# nrf51 register map
Vendor: Nordic Semiconductor; Series: nrf51; File version: 522
CPU: CM0 r3p1, little endian, no MPU, no FPU, 2 interrupt priority bits
Registers are 32-bit, read-write, reset 0x0 unless marked. A register's access mark holds for its fields unless they carry their own. Offsets are from the block's base; [hi:lo] are bit positions; {n}, {i} and the like mark numbered series; 'fields as' and 'values as' point back to an identical list.

## QDEC — Rotary decoder.
Base 0x40012000
0x00 TASKS_START wo — Start the quadrature decoder.
0x04 TASKS_STOP wo — Stop the quadrature decoder.
0x08 TASKS_READCLRACC wo — Transfers the content from ACC registers to ACCREAD registers, and clears the ACC registers.
0x100 EVENTS_SAMPLERDY — A new sample is written to the sample register.
0x104 EVENTS_REPORTRDY — REPORTPER number of samples accumulated in ACC register, and ACC register different than zero.
0x108 EVENTS_ACCOF — ACC or ACCDBL register overflow.
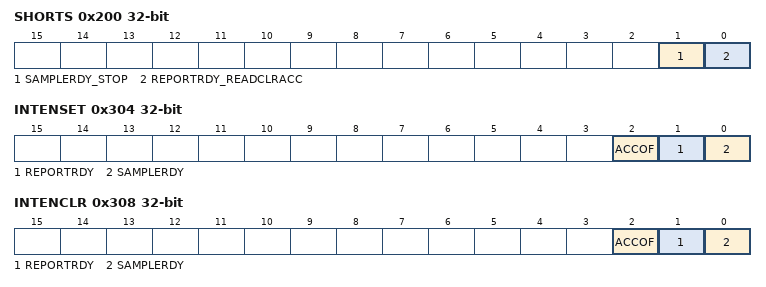
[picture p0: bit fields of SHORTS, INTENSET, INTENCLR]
0x200 SHORTS — Shortcuts for the QDEC.
  [1] SAMPLERDY_STOP — Shortcut between SAMPLERDY event and STOP task.
    0=Disabled (Shortcut disabled.); 1=Enabled (Shortcut enabled.)
  [0] REPORTRDY_READCLRACC — Shortcut between REPORTRDY event and READCLRACC task.
    values as SAMPLERDY_STOP
0x304 INTENSET — Interrupt enable set register.
  [all] fields
    on read: 0=Disabled (Interrupt disabled.); 1=Enabled (Interrupt enabled.) | on write: 1=Set (Enable interrupt on write.)
  [2] ACCOF — Enable interrupt on ACCOF event.
  [1] REPORTRDY — Enable interrupt on REPORTRDY event.
  [0] SAMPLERDY — Enable interrupt on SAMPLERDY event.
0x308 INTENCLR — Interrupt enable clear register.
  [all] fields
    on read: 0=Disabled (Interrupt disabled.); 1=Enabled (Interrupt enabled.) | on write: 1=Clear (Disable interrupt on write.)
  [2] ACCOF — Disable interrupt on ACCOF event.
  [1] REPORTRDY — Disable interrupt on REPORTRDY event.
  [0] SAMPLERDY — Disable interrupt on SAMPLERDY event.
0x500 ENABLE — Enable the QDEC.
  [0] ENABLE — Enable or disable QDEC.
    0=Disabled QDEC; 1=Enabled (Enable QDEC.)
0x504 LEDPOL — LED output pin polarity.
  [0] LEDPOL
    0=ActiveLow (LED output is active low.); 1=ActiveHigh (LED output is active high.)
0x508 SAMPLEPER — Sample period.
  [2:0] SAMPLEPER
    0=128us sample period; 1=256us sample period; 2=512us sample period; 3=1024us sample period; 4=2048us sample period; 5=4096us sample period; 6=8192us sample period; 7=16384us sample period
0x50C SAMPLE ro — Motion sample value.
  [31:0] SAMPLE — Last sample taken in compliment to 2.
0x510 REPORTPER — Number of samples to generate an EVENT_REPORTRDY.
  [2:0] REPORTPER
    0=10Smpl (10 samples per report.); 1=40Smpl (40 samples per report.); 2=80Smpl (80 samples per report.); 3=120Smpl (120 samples per report.); 4=160Smpl (160 samples per report.); 5=200Smpl (200 samples per report.); 6=240Smpl (240 samples per report.); 7=280Smpl (280 samples per report.)
0x514 ACC ro — Accumulated valid transitions register.
0x518 ACCREAD ro — Snapshot of ACC register. Value generated by the TASKS_READCLEACC task.
0x51C PSELLED reset 0xFFFFFFFF — Pin select for LED output.
0x520 PSELA reset 0xFFFFFFFF — Pin select for phase A input.
0x524 PSELB reset 0xFFFFFFFF — Pin select for phase B input.
0x528 DBFEN — Enable debouncer input filters.
  [0] DBFEN — Enable debounce input filters.
    0=Disabled (Debounce input filters disabled.); 1=Enabled (Debounce input filters enabled.)
0x540 LEDPRE reset 0x10 — Time LED is switched ON before the sample.
  [8:0] LEDPRE — Period in us the LED in switched on prior to sampling.
0x544 ACCDBL ro — Accumulated double (error) transitions register.
  [3:0] ACCDBL — Accumulated double (error) transitions.
0x548 ACCDBLREAD ro — Snapshot of ACCDBL register. Value generated by the TASKS_READCLEACC task.
  [3:0] ACCDBLREAD — Snapshot of accumulated double (error) transitions.
0xFFC POWER — Peripheral power control.
  [0] POWER
    0=Disabled (Module power disabled.); 1=Enabled (Module power enabled.)

## LPCOMP — Low power comparator.
Base 0x40013000
0x00 TASKS_START wo — Start the comparator.
0x04 TASKS_STOP wo — Stop the comparator.
0x08 TASKS_SAMPLE wo — Sample comparator value.
0x100 EVENTS_READY — LPCOMP is ready and output is valid.
0x104 EVENTS_DOWN — Input voltage crossed the threshold going down.
0x108 EVENTS_UP — Input voltage crossed the threshold going up.
0x10C EVENTS_CROSS — Input voltage crossed the threshold in any direction.
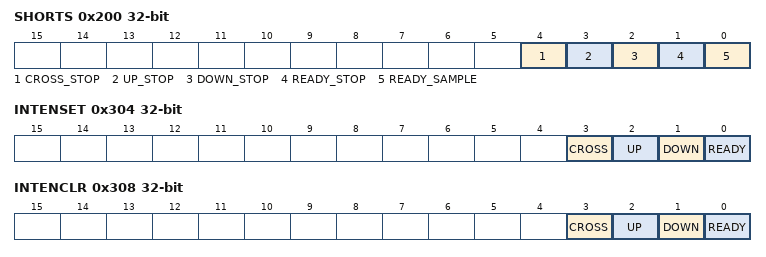
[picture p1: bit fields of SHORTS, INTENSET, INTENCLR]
0x200 SHORTS — Shortcuts for the LPCOMP.
  [all] fields
    0=Disabled (Shortcut disabled.); 1=Enabled (Shortcut enabled.)
  [4] CROSS_STOP — Shortcut between CROSS event and STOP task.
  [3] UP_STOP — Shortcut between UP event and STOP task.
  [2] DOWN_STOP — Shortcut between DOWN event and STOP task.
  [1] READY_STOP — Shortcut between RADY event and STOP task.
  [0] READY_SAMPLE — Shortcut between READY event and SAMPLE task.
0x304 INTENSET — Interrupt enable set register.
  [all] fields
    on read: 0=Disabled (Interrupt disabled.); 1=Enabled (Interrupt enabled.) | on write: 1=Set (Enable interrupt on write.)
  [3] CROSS — Enable interrupt on CROSS event.
  [2] UP — Enable interrupt on UP event.
  [1] DOWN — Enable interrupt on DOWN event.
  [0] READY — Enable interrupt on READY event.
0x308 INTENCLR — Interrupt enable clear register.
  [all] fields
    on read: 0=Disabled (Interrupt disabled.); 1=Enabled (Interrupt enabled.) | on write: 1=Clear (Disable interrupt on write.)
  [3] CROSS — Disable interrupt on CROSS event.
  [2] UP — Disable interrupt on UP event.
  [1] DOWN — Disable interrupt on DOWN event.
  [0] READY — Disable interrupt on READY event.
0x400 RESULT ro — Result of last compare.
  [0] RESULT — Result of last compare. Decision point SAMPLE task.
    0=Below (Input voltage is bellow the reference threshold.); 1=Above (Input voltage is above the reference threshold.)
0x500 ENABLE — Enable the LPCOMP.
  [1:0] ENABLE — Enable or disable LPCOMP.
    0=Disabled LPCOMP; 1=Enabled (Enable LPCOMP.)
0x504 PSEL — Input pin select.
  [2:0] PSEL — Analog input pin select.
    {v}=AnalogInput{v} (Use analog input {v} as analog input.) (v=0..7)
0x508 REFSEL — Reference select.
  [2:0] REFSEL
    0=SupplyOneEighthPrescaling (Use supply with a 1/8 prescaler as reference.); 1=SupplyTwoEighthsPrescaling (Use supply with a 2/8 prescaler as reference.); 2=SupplyThreeEighthsPrescaling (Use supply with a 3/8 prescaler as reference.); 3=SupplyFourEighthsPrescaling (Use supply with a 4/8 prescaler as reference.); 4=SupplyFiveEighthsPrescaling (Use supply with a 5/8 prescaler as reference.); 5=SupplySixEighthsPrescaling (Use supply with a 6/8 prescaler as reference.); 6=SupplySevenEighthsPrescaling (Use supply with a 7/8 prescaler as reference.); 7=ARef (Use external analog reference as reference.)
0x50C EXTREFSEL — External reference select.
  [0] EXTREFSEL — External analog reference pin selection.
    0=AnalogReference0 (Use analog reference 0 as reference.); 1=AnalogReference1 (Use analog reference 1 as reference.)
0x520 ANADETECT — Analog detect configuration.
  [1:0] ANADETECT
    0=Cross (Generate ANADETEC on crossing, both upwards and downwards crossing.); 1=Up (Generate ANADETEC on upwards crossing only.); 2=Down (Generate ANADETEC on downwards crossing only.)
0xFFC POWER — Peripheral power control.
  [0] POWER
    0=Disabled (Module power disabled.); 1=Enabled (Module power enabled.)
